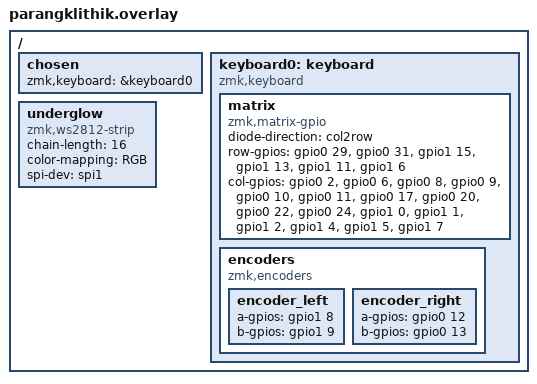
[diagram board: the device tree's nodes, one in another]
// This file was generated from a template. Edit it to match your keyboard.
// See https://zmk.dev/docs/development/hardware-integration/new-shield for more
// instructions.

#include <dt-bindings/zmk/matrix_transform.h>

#include "parangklithik-layouts.dtsi"

/ {
    chosen {
        zmk,keyboard = &keyboard0;
    };

    keyboard0: keyboard {
        compatible = "zmk,keyboard";

        matrix {
            compatible = "zmk,matrix-gpio";
            diode-direction = "col2row";

            row-gpios = <
                &gpio0 29 GPIO_ACTIVE_HIGH
                &gpio0 31 GPIO_ACTIVE_HIGH
                &gpio1 15 GPIO_ACTIVE_HIGH
                &gpio1 13 GPIO_ACTIVE_HIGH
                &gpio1 11 GPIO_ACTIVE_HIGH
                &gpio1 6 GPIO_ACTIVE_HIGH
            >;

            col-gpios = <
                &gpio0 2 GPIO_ACTIVE_HIGH
                &gpio0 6 GPIO_ACTIVE_HIGH
                &gpio0 8 GPIO_ACTIVE_HIGH
                &gpio0 9 GPIO_ACTIVE_HIGH
                &gpio0 10 GPIO_ACTIVE_HIGH
                &gpio0 11 GPIO_ACTIVE_HIGH
                &gpio0 17 GPIO_ACTIVE_HIGH
                &gpio0 20 GPIO_ACTIVE_HIGH
                &gpio0 22 GPIO_ACTIVE_HIGH
                &gpio0 24 GPIO_ACTIVE_HIGH
                &gpio1 0 GPIO_ACTIVE_HIGH
                &gpio1 1 GPIO_ACTIVE_HIGH
                &gpio1 2 GPIO_ACTIVE_HIGH
                &gpio1 4 GPIO_ACTIVE_HIGH
                &gpio1 5 GPIO_ACTIVE_HIGH
                &gpio1 7 GPIO_ACTIVE_HIGH
            >;
        };

        encoders {
            compatible = "zmk,encoders";

            encoder_left: encoder_left {
                a-gpios = <&gpio1 8 GPIO_ACTIVE_HIGH>;
                b-gpios = <&gpio1 9 GPIO_ACTIVE_HIGH>;
            };

            encoder_right: encoder_right {
                a-gpios = <&gpio0 12 GPIO_ACTIVE_HIGH>;
                b-gpios = <&gpio0 13 GPIO_ACTIVE_HIGH>;
            };
        };
    };

    underglow {
        compatible = "zmk,ws2812-strip";
        chain-length = <16>;
        color-mapping = <RGB>;
        spi-dev = <&spi1>;
    };
};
